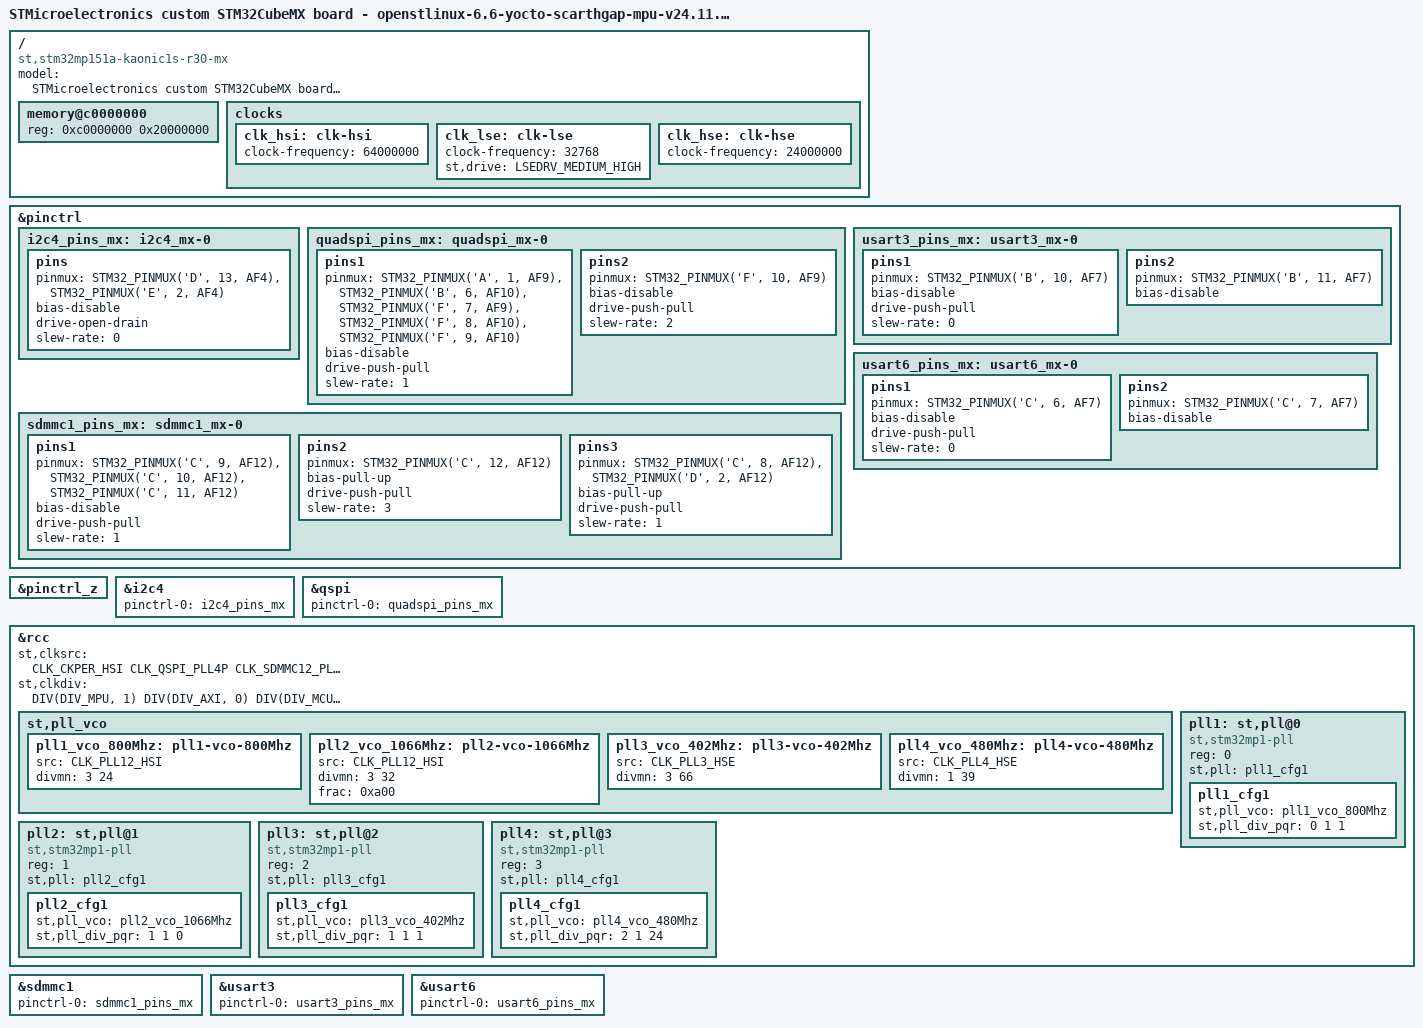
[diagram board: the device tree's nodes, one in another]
// SPDX-License-Identifier: (GPL-2.0-or-later OR BSD-3-Clause)
/*
 * Copyright (C) 2026, STMicroelectronics - All Rights Reserved
 * Author: STM32CubeMX code generation for STMicroelectronics.
 */

/* For more information on Device Tree configuration, please refer to
 * https://wiki.st.com/stm32mpu/wiki/Category:Device_tree_configuration
 */

/dts-v1/;

#include <dt-bindings/pinctrl/stm32-pinfunc.h>
#include <dt-bindings/clock/stm32mp1-clksrc.h>
#include "stm32mp15-mx.dtsi"

#include "stm32mp151.dtsi"
#include "stm32mp15xa.dtsi"
#include "stm32mp15xxab-pinctrl.dtsi"
#include "stm32mp15-ddr.dtsi"

/* USER CODE BEGIN includes */
/* USER CODE END includes */

/ {
	model = "STMicroelectronics custom STM32CubeMX board - openstlinux-6.6-yocto-scarthgap-mpu-v24.11.06";
	compatible = "st,stm32mp151a-kaonic1s-r30-mx", "st,stm32mp151";

	memory@c0000000 {
		device_type = "memory";
		reg = <0xc0000000 0x20000000>;

		/* USER CODE BEGIN memory */
		/* USER CODE END memory */
	};

	/* USER CODE BEGIN root */
	/* USER CODE END root */

	clocks {
		/* USER CODE BEGIN clocks */
		/* USER CODE END clocks */

		clk_hsi: clk-hsi {
			clock-frequency = <64000000>;

			/* USER CODE BEGIN clk_hsi */
			/* USER CODE END clk_hsi */
		};
		clk_lse: clk-lse {
			clock-frequency = <32768>;
			st,drive = < LSEDRV_MEDIUM_HIGH >;

			/* USER CODE BEGIN clk_lse */
			/* USER CODE END clk_lse */
		};
		clk_hse: clk-hse {
			clock-frequency = <24000000>;

			/* USER CODE BEGIN clk_hse */
			/* USER CODE END clk_hse */
		};
	};

}; /*root*/

&pinctrl {
	i2c4_pins_mx: i2c4_mx-0 {
		pins {
			pinmux = <STM32_PINMUX('D', 13, AF4)>, /* I2C4_SDA */
					 <STM32_PINMUX('E', 2, AF4)>; /* I2C4_SCL */
			bias-disable;
			drive-open-drain;
			slew-rate = <0>;
		};
	};

	quadspi_pins_mx: quadspi_mx-0 {
		pins1 {
			pinmux = <STM32_PINMUX('A', 1, AF9)>, /* QUADSPI_BK1_IO3 */
					 <STM32_PINMUX('B', 6, AF10)>, /* QUADSPI_BK1_NCS */
					 <STM32_PINMUX('F', 7, AF9)>, /* QUADSPI_BK1_IO2 */
					 <STM32_PINMUX('F', 8, AF10)>, /* QUADSPI_BK1_IO0 */
					 <STM32_PINMUX('F', 9, AF10)>; /* QUADSPI_BK1_IO1 */
			bias-disable;
			drive-push-pull;
			slew-rate = <1>;
		};
		pins2 {
			pinmux = <STM32_PINMUX('F', 10, AF9)>; /* QUADSPI_CLK */
			bias-disable;
			drive-push-pull;
			slew-rate = <2>;
		};
	};

	sdmmc1_pins_mx: sdmmc1_mx-0 {
		pins1 {
			pinmux = <STM32_PINMUX('C', 9, AF12)>, /* SDMMC1_D1 */
					 <STM32_PINMUX('C', 10, AF12)>, /* SDMMC1_D2 */
					 <STM32_PINMUX('C', 11, AF12)>; /* SDMMC1_D3 */
			bias-disable;
			drive-push-pull;
			slew-rate = <1>;
		};
		pins2 {
			pinmux = <STM32_PINMUX('C', 12, AF12)>; /* SDMMC1_CK */
			bias-pull-up;
			drive-push-pull;
			slew-rate = <3>;
		};
		pins3 {
			pinmux = <STM32_PINMUX('C', 8, AF12)>, /* SDMMC1_D0 */
					 <STM32_PINMUX('D', 2, AF12)>; /* SDMMC1_CMD */
			bias-pull-up;
			drive-push-pull;
			slew-rate = <1>;
		};
	};

	usart3_pins_mx: usart3_mx-0 {
		pins1 {
			pinmux = <STM32_PINMUX('B', 10, AF7)>; /* USART3_TX */
			bias-disable;
			drive-push-pull;
			slew-rate = <0>;
		};
		pins2 {
			pinmux = <STM32_PINMUX('B', 11, AF7)>; /* USART3_RX */
			bias-disable;
		};
	};

	usart6_pins_mx: usart6_mx-0 {
		pins1 {
			pinmux = <STM32_PINMUX('C', 6, AF7)>; /* USART6_TX */
			bias-disable;
			drive-push-pull;
			slew-rate = <0>;
		};
		pins2 {
			pinmux = <STM32_PINMUX('C', 7, AF7)>; /* USART6_RX */
			bias-disable;
		};
	};

	/* USER CODE BEGIN pinctrl */
	/* USER CODE END pinctrl */
};

&pinctrl_z {
	/* USER CODE BEGIN pinctrl_z */
	/* USER CODE END pinctrl_z */
};

&i2c4 {
	pinctrl-names = "default";
	pinctrl-0 = <&i2c4_pins_mx>;
	status = "okay";

	/* USER CODE BEGIN i2c4 */
	/* USER CODE END i2c4 */
};

&qspi {
	pinctrl-names = "default";
	pinctrl-0 = <&quadspi_pins_mx>;
	status = "okay";

	/* USER CODE BEGIN qspi */
	/* USER CODE END qspi */
};

&rcc {
	status = "okay";

	/* USER CODE BEGIN rcc */
	/* USER CODE END rcc */

	st,clksrc = <
		CLK_CKPER_HSI
		CLK_QSPI_PLL4P
		CLK_SDMMC12_PLL4P
		CLK_STGEN_HSE
		CLK_I2C46_HSI
		CLK_UART35_PCLK1
		CLK_UART6_PCLK2
		CLK_MPU_PLL1P
		CLK_AXI_PLL2P
		CLK_MCU_PLL3P
	>;
	st,clkdiv = <
		DIV(DIV_MPU, 1)
		DIV(DIV_AXI, 0)
		DIV(DIV_MCU, 0)
		DIV(DIV_APB1, 1)
		DIV(DIV_APB2, 1)
		DIV(DIV_APB3, 1)
		DIV(DIV_APB4, 1)
		DIV(DIV_APB5, 2)
		DIV(DIV_RTC, 0)
		DIV(DIV_MCO1, 0)
		DIV(DIV_MCO2, 0)
	>;
	st,pll_vco {
		pll1_vco_800Mhz: pll1-vco-800Mhz {
			src = < CLK_PLL12_HSI >;
			divmn = < 3 24 >;
		};
		pll2_vco_1066Mhz: pll2-vco-1066Mhz {
			src = < CLK_PLL12_HSI >;
			divmn = < 3 32 >;
			frac = < 0xa00 >;
		};
		pll3_vco_402Mhz: pll3-vco-402Mhz {
			src = < CLK_PLL3_HSE >;
			divmn = < 3 66 >;
		};
		pll4_vco_480Mhz: pll4-vco-480Mhz {
			src = < CLK_PLL4_HSE >;
			divmn = < 1 39 >;
		};
		/* USER CODE BEGIN rcc_st-pll_vco */
		/* USER CODE END rcc_st-pll_vco */
	};

	pll1:st,pll@0 {
		compatible = "st,stm32mp1-pll";
		reg = <0>;

		st,pll = < &pll1_cfg1 >;

		pll1_cfg1: pll1_cfg1 {
			st,pll_vco = < &pll1_vco_800Mhz >;
			st,pll_div_pqr = < 0 1 1 >;
		};
		/* USER CODE BEGIN pll1 */
		/* USER CODE END pll1 */
	};

	pll2:st,pll@1 {
		compatible = "st,stm32mp1-pll";
		reg = <1>;

		st,pll = < &pll2_cfg1 >;

		pll2_cfg1: pll2_cfg1 {
			st,pll_vco = < &pll2_vco_1066Mhz >;
			st,pll_div_pqr = < 1 1 0 >;
		};
		/* USER CODE BEGIN pll2 */
		/* USER CODE END pll2 */
	};

	pll3:st,pll@2 {
		compatible = "st,stm32mp1-pll";
		reg = <2>;

		st,pll = < &pll3_cfg1 >;

		pll3_cfg1: pll3_cfg1 {
			st,pll_vco = < &pll3_vco_402Mhz >;
			st,pll_div_pqr = < 1 1 1 >;
		};
		/* USER CODE BEGIN pll3 */
		/* USER CODE END pll3 */
	};

	pll4:st,pll@3 {
		compatible = "st,stm32mp1-pll";
		reg = <3>;

		st,pll = < &pll4_cfg1 >;

		pll4_cfg1: pll4_cfg1 {
			st,pll_vco = < &pll4_vco_480Mhz >;
			st,pll_div_pqr = < 2 1 24 >;
		};
		/* USER CODE BEGIN pll4 */
		/* USER CODE END pll4 */
	};

};

&sdmmc1 {
	pinctrl-names = "default";
	pinctrl-0 = <&sdmmc1_pins_mx>;
	status = "okay";

	/* USER CODE BEGIN sdmmc1 */
	/* USER CODE END sdmmc1 */
};

&usart3 {
	pinctrl-names = "default";
	pinctrl-0 = <&usart3_pins_mx>;
	status = "okay";

	/* USER CODE BEGIN usart3 */
	/* USER CODE END usart3 */
};

&usart6 {
	pinctrl-names = "default";
	pinctrl-0 = <&usart6_pins_mx>;
	status = "okay";

	/* USER CODE BEGIN usart6 */
	/* USER CODE END usart6 */
};

/* USER CODE BEGIN addons */
/* USER CODE END addons */

